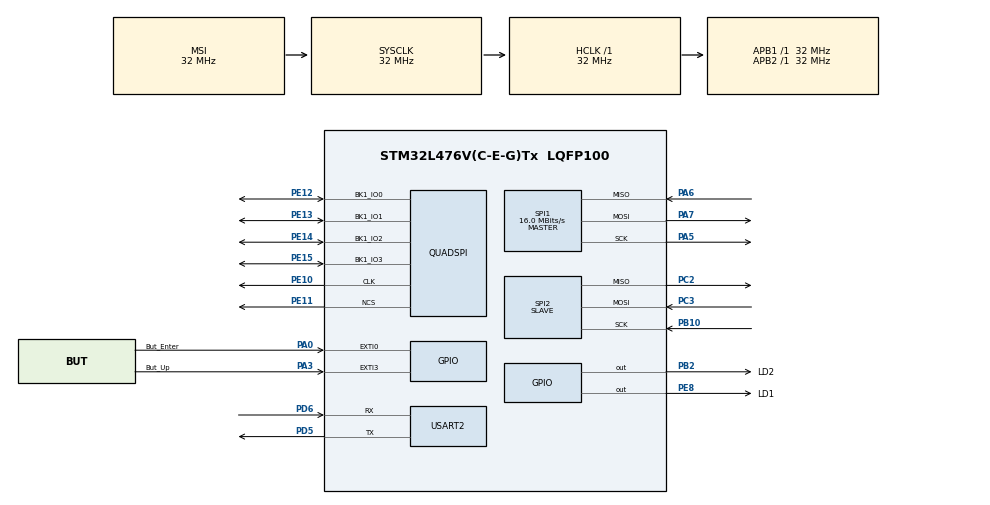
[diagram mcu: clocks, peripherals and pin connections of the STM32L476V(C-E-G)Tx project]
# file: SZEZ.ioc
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Mcu.Family=STM32L4
Mcu.Name=STM32L476V(C-E-G)Tx
Mcu.Package=LQFP100
NVIC.EXTI0_IRQn=true\:0\:0\:false\:false\:true\:true\:true
NVIC.EXTI3_IRQn=true\:0\:0\:false\:false\:true\:true\:true
NVIC.PriorityGroup=NVIC_PRIORITYGROUP_4
NVIC.USART2_IRQn=true\:0\:0\:false\:false\:true\:true\:true
PA0.GPIO_Label=But_Enter
PA0.Signal=GPXTI0
PA3.GPIO_Label=But_Up
PA3.Signal=GPXTI3
PA5.Mode=Full_Duplex_Master
PA5.Signal=SPI1_SCK
PA6.Mode=Full_Duplex_Master
PA6.Signal=SPI1_MISO
PA7.Mode=Full_Duplex_Master
PA7.Signal=SPI1_MOSI
PB10.Mode=Full_Duplex_Slave
PB10.Signal=SPI2_SCK
PB2.GPIO_Label=LD2
PB2.Signal=GPIO_Output
PC2.Mode=Full_Duplex_Slave
PC2.Signal=SPI2_MISO
PC3.Mode=Full_Duplex_Slave
PC3.Signal=SPI2_MOSI
PD5.Mode=Asynchronous
PD5.Signal=USART2_TX
PD6.Mode=Asynchronous
PD6.Signal=USART2_RX
PE10.Mode=Single Bank
PE10.Signal=QUADSPI_CLK
PE11.Mode=Single Bank
PE11.Signal=QUADSPI_NCS
PE12.Mode=Single Bank
PE12.Signal=QUADSPI_BK1_IO0
PE13.Mode=Single Bank
PE13.Signal=QUADSPI_BK1_IO1
PE14.Mode=Single Bank
PE14.Signal=QUADSPI_BK1_IO2
PE15.Mode=Single Bank
PE15.Signal=QUADSPI_BK1_IO3
PE8.GPIO_Label=LD1
PE8.Signal=GPIO_Output
ProjectManager.HeapSize=0x200
ProjectManager.StackSize=0x400
ProjectManager.TargetToolchain=TrueSTUDIO
RCC.ADCFreq_Value=128000000
RCC.AHBFreq_Value=32000000
RCC.APB1Freq_Value=32000000
RCC.APB1TimFreq_Value=32000000
RCC.APB2Freq_Value=32000000
RCC.APB2TimFreq_Value=32000000
RCC.CortexFreq_Value=32000000
RCC.HCLKFreq_Value=32000000
RCC.HSE_VALUE=8000000
RCC.HSI_VALUE=16000000
RCC.LSE_VALUE=32768
RCC.MSIClockRange=RCC_MSIRANGE_10
RCC.MSI_VALUE=32000000
RCC.PREFETCH_ENABLE=1
RCC.SYSCLKFreq_VALUE=32000000
RCC.USBFreq_Value=128000000
RCC.VCOOutputFreq_Value=256000000
SPI1.CalculateBaudRate=16.0 MBits/s
SPI1.Direction=SPI_DIRECTION_2LINES
SPI1.Mode=SPI_MODE_MASTER
SPI1.VirtualType=VM_MASTER
SPI2.Direction=SPI_DIRECTION_2LINES
SPI2.Mode=SPI_MODE_SLAVE
SPI2.VirtualType=VM_SLAVE
USART2.VirtualMode-Asynchronous=VM_ASYNC
board=32L476GDISCOVERY

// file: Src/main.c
/* USER CODE BEGIN Header */
/**
  ******************************************************************************
  * @file           : main.c
  * @brief          : Main program body
  ******************************************************************************
  * @attention
  *
  * <h2><center>&copy; Copyright (c) 2019 STMicroelectronics.
  * All rights reserved.</center></h2>
  *
  * This software component is licensed by ST under BSD 3-Clause license,
  * the "License"; You may not use this file except in compliance with the
  * License. You may obtain a copy of the License at:
  *                        opensource.org/licenses/BSD-3-Clause
  *
  ******************************************************************************
  */
/* USER CODE END Header */

#include "main.h"
#include "quadspi.h"
#include "spi.h"
#include "usart.h"
#include "gpio.h"

/* USER CODE BEGIN PV */
volatile uint8_t FlagEnter = 0;
volatile uint8_t FlagUp = 0;
/* USER CODE END PV */

void SystemClock_Config(void);
/* USER CODE BEGIN PFP */
void HAL_GPIO_EXTI_Callback(uint16_t GPIO_Pin)
{
	 if(GPIO_Pin == But_Enter_Pin)
		 HAL_GPIO_TogglePin(LD1_GPIO_Port, LD1_Pin);
		 //FlagEnter = 1;

	 if(GPIO_Pin == But_Up_Pin)
		 FlagUp = 1;

}

/* USER CODE END PFP */

int main(void)
{

  /* MCU Configuration--------------------------------------------------------*/

  /* Reset of all peripherals, Initializes the Flash interface and the Systick. */
  HAL_Init();

  /* Configure the system clock */
  SystemClock_Config();

  /* Initialize all configured peripherals */
  MX_GPIO_Init();
  MX_QUADSPI_Init();
  MX_SPI1_Init();
  MX_SPI2_Init();
  MX_USART2_UART_Init();
  /* USER CODE BEGIN 2 */
  HAL_GPIO_TogglePin(LD1_GPIO_Port, LD1_Pin);
  /* USER CODE END 2 */

  /* Infinite loop */
  /* USER CODE BEGIN WHILE */
  while (1)
  {
	  if (FlagEnter == 1)
	  {
		  HAL_GPIO_TogglePin(LD1_GPIO_Port, LD1_Pin);

		  FlagEnter = 0;
	  }

	  if (FlagUp == 1)
	  {
		  HAL_GPIO_TogglePin(LD2_GPIO_Port, LD2_Pin);

		  FlagEnter = 0;
	  }
    /* USER CODE END WHILE */
  }
}

void SystemClock_Config(void)
{
  RCC_OscInitTypeDef RCC_OscInitStruct = {0};
  RCC_ClkInitTypeDef RCC_ClkInitStruct = {0};
  RCC_PeriphCLKInitTypeDef PeriphClkInit = {0};

  /** Initializes the CPU, AHB and APB busses clocks
  */
  RCC_OscInitStruct.OscillatorType = RCC_OSCILLATORTYPE_MSI;
  RCC_OscInitStruct.MSIState = RCC_MSI_ON;
  RCC_OscInitStruct.MSICalibrationValue = 0;
  RCC_OscInitStruct.MSIClockRange = RCC_MSIRANGE_10;
  RCC_OscInitStruct.PLL.PLLState = RCC_PLL_NONE;
  if (HAL_RCC_OscConfig(&RCC_OscInitStruct) != HAL_OK)
  {
    Error_Handler();
  }
  /** Initializes the CPU, AHB and APB busses clocks
  */
  RCC_ClkInitStruct.ClockType = RCC_CLOCKTYPE_HCLK|RCC_CLOCKTYPE_SYSCLK
                              |RCC_CLOCKTYPE_PCLK1|RCC_CLOCKTYPE_PCLK2;
  RCC_ClkInitStruct.SYSCLKSource = RCC_SYSCLKSOURCE_MSI;
  RCC_ClkInitStruct.AHBCLKDivider = RCC_SYSCLK_DIV1;
  RCC_ClkInitStruct.APB1CLKDivider = RCC_HCLK_DIV1;
  RCC_ClkInitStruct.APB2CLKDivider = RCC_HCLK_DIV1;

  if (HAL_RCC_ClockConfig(&RCC_ClkInitStruct, FLASH_LATENCY_1) != HAL_OK)
  {
    Error_Handler();
  }
  PeriphClkInit.PeriphClockSelection = RCC_PERIPHCLK_USART2;
  PeriphClkInit.Usart2ClockSelection = RCC_USART2CLKSOURCE_PCLK1;
  if (HAL_RCCEx_PeriphCLKConfig(&PeriphClkInit) != HAL_OK)
  {
    Error_Handler();
  }
  /** Configure the main internal regulator output voltage
  */
  if (HAL_PWREx_ControlVoltageScaling(PWR_REGULATOR_VOLTAGE_SCALE1) != HAL_OK)
  {
    Error_Handler();
  }
}

void Error_Handler(void)
{
}

/************************ (C) COPYRIGHT STMicroelectronics *****END OF FILE****/
